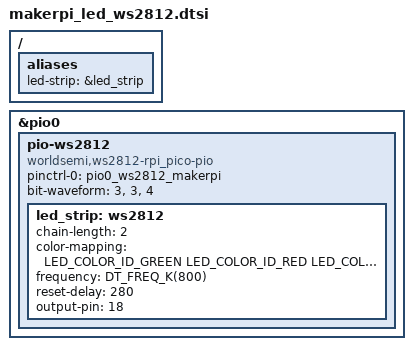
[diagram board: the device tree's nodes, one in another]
/*
 * Copyright (c) 2023 TiaC Systems
 * SPDX-License-Identifier: Apache-2.0
 */

#include <freq.h>
#include <zephyr/dt-bindings/gpio/gpio.h>
#include <zephyr/dt-bindings/led/led.h>

/ {
	aliases {
		led-strip = &led_strip;
	};
};

&pio0 {
	status = "okay";

	pio-ws2812 {
		compatible = "worldsemi,ws2812-rpi_pico-pio";
		status = "okay";

		pinctrl-0 = <&pio0_ws2812_makerpi>;
		pinctrl-names = "default";
		bit-waveform = <3>, <3>, <4>;

		led_strip: ws2812 {
			status = "okay";

			chain-length = <2>;
			color-mapping = <LED_COLOR_ID_GREEN
					 LED_COLOR_ID_RED
					 LED_COLOR_ID_BLUE>;

			frequency = <DT_FREQ_K(800)>;
			reset-delay = <280>;
			output-pin = <18>;	/* PIO0:OUT @ GP18 */
		};
	};
};
